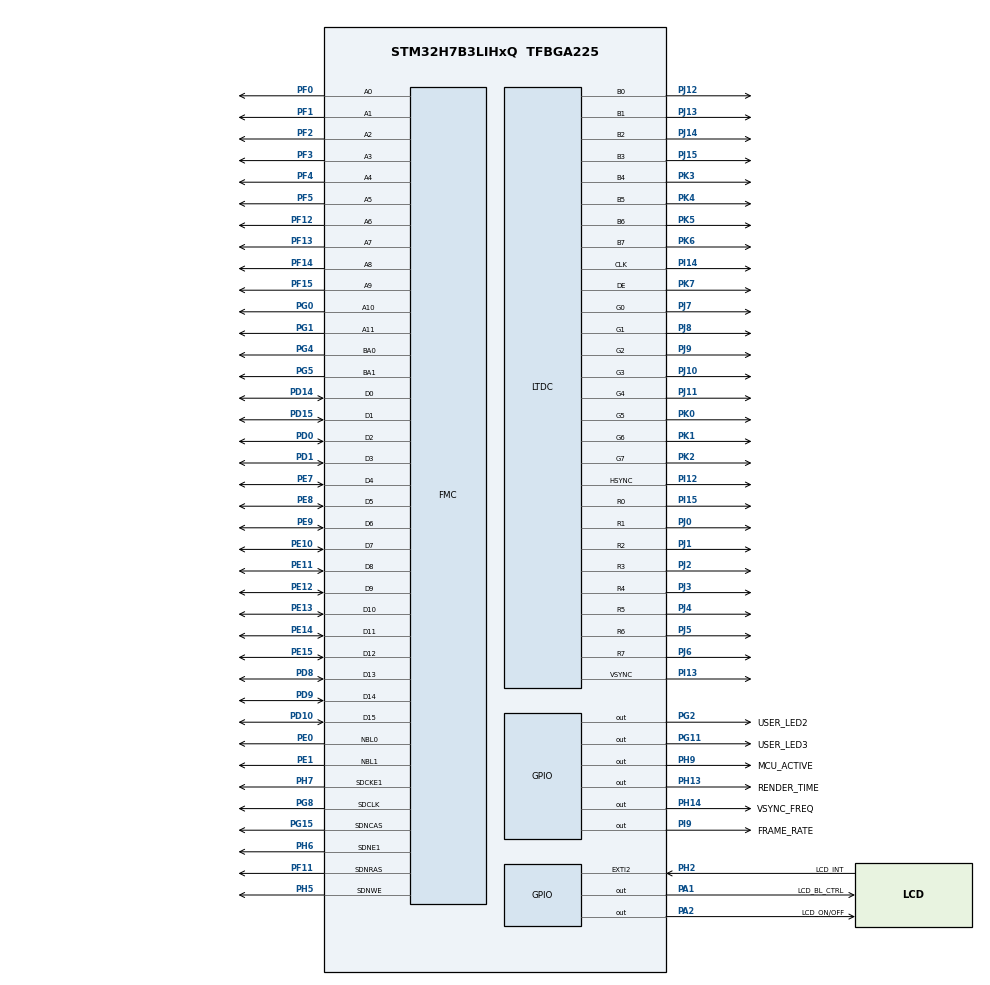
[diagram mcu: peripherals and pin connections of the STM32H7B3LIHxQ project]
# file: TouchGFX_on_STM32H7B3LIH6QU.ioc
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CORTEX_M7.default_mode_Activation=1
DMA2D.ColorMode=DMA2D_OUTPUT_RGB888
FMC.CASLatency1=FMC_SDRAM_CAS_LATENCY_2
FMC.ColumnBitsNumber1=FMC_SDRAM_COLUMN_BITS_NUM_9
FMC.ExitSelfRefreshDelay1=7
FMC.LoadToActiveDelay1=2
FMC.RCDDelay1=2
FMC.RPDelay1=2
FMC.ReadBurst1=FMC_SDRAM_RBURST_ENABLE
FMC.ReadPipeDelay1=FMC_SDRAM_RPIPE_DELAY_2
FMC.RowCycleDelay1=7
FMC.SDClockPeriod1=FMC_SDRAM_CLOCK_PERIOD_3
FMC.SelfRefreshTime1=4
FMC.WriteRecoveryTime1=3
FREERTOS.INCLUDE_vTaskCleanUpResources=0
FREERTOS.Tasks01=defaultTask,24,128,StartDefaultTask,Default,NULL,Dynamic,NULL,NULL;GUI_Task,24,8192,StartGUI_Task,Default,NULL,Dynamic,NULL,NULL
FREERTOS.configENABLE_FPU=0
FREERTOS.configTOTAL_HEAP_SIZE=100000
FREERTOS.configUSE_APPLICATION_TASK_TAG=1
FREERTOS.configUSE_IDLE_HOOK=1
FREERTOS.configUSE_NEWLIB_REENTRANT=1
LTDC.ActiveH=272
LTDC.ActiveW=480
LTDC.Alpha_L0=255
LTDC.Blue_L0=255
LTDC.FBStartAdress_L0=0xD0000000
LTDC.HBP=2
LTDC.HFP=32
LTDC.HSync=41
LTDC.ImageHeight_L0=272
LTDC.ImageWidth_L0=480
LTDC.Layers=0
LTDC.PixelFormat_L0=LTDC_PIXEL_FORMAT_RGB888
LTDC.VSync=10
LTDC.WindowX1_L0=480
LTDC.WindowY1_L0=272
Mcu.Family=STM32H7
Mcu.Name=STM32H7B3LIHxQ
Mcu.Package=TFBGA225
NVIC.DMA2D_IRQn=true\:5\:0\:false\:false\:true\:true\:true\:true\:true
NVIC.EXTI2_IRQn=true\:5\:0\:false\:false\:true\:false\:true\:true\:true
NVIC.LTDC_IRQn=true\:5\:0\:false\:false\:true\:true\:true\:true\:true
NVIC.PriorityGroup=NVIC_PRIORITYGROUP_4
NVIC.TIM6_DAC_IRQn=true\:0\:0\:true\:false\:true\:false\:false\:true\:true
NVIC.TimeBase=TIM6_DAC_IRQn
NVIC.TimeBaseIP=TIM6
OCTOSPI1.ChipSelectHighTime=2
OCTOSPI1.DeviceSize=26
PA1.GPIO_Label=LCD_BL_CTRL
PA1.PinState=GPIO_PIN_SET
PA1.Signal=GPIO_Output
PA13.Mode=Serial_Wire
PA13.Signal=DEBUG_JTMS-SWDIO
PA14.Mode=Serial_Wire
PA14.Signal=DEBUG_JTCK-SWCLK
PA2.GPIO_Label=LCD_ON/OFF
PA2.GPIO_PuPd=GPIO_PULLUP
PA2.PinState=GPIO_PIN_SET
PA2.Signal=GPIO_Output
PD0.Signal=FMC_D2_DA2
PD1.Signal=FMC_D3_DA3
PD10.Signal=FMC_D15_DA15
PD14.Signal=FMC_D0_DA0
PD15.Signal=FMC_D1_DA1
PD8.Signal=FMC_D13_DA13
PD9.Signal=FMC_D14_DA14
PE0.Signal=FMC_NBL0
PE1.Signal=FMC_NBL1
PE10.Signal=FMC_D7_DA7
PE11.Signal=FMC_D8_DA8
PE12.Signal=FMC_D9_DA9
PE13.Signal=FMC_D10_DA10
PE14.Signal=FMC_D11_DA11
PE15.Signal=FMC_D12_DA12
PE7.Signal=FMC_D4_DA4
PE8.Signal=FMC_D5_DA5
PE9.Signal=FMC_D6_DA6
PF0.Signal=FMC_A0
PF1.Signal=FMC_A1
PF11.Signal=FMC_SDNRAS
PF12.Signal=FMC_A6
PF13.Signal=FMC_A7
PF14.Signal=FMC_A8
PF15.Signal=FMC_A9
PF2.Signal=FMC_A2
PF3.Signal=FMC_A3
PF4.Signal=FMC_A4
PF5.Signal=FMC_A5
PG0.Signal=FMC_A10
PG1.Signal=FMC_A11
PG11.GPIO_Label=USER_LED3
PG11.PinState=GPIO_PIN_SET
PG11.Signal=GPIO_Output
PG15.Signal=FMC_SDNCAS
PG2.GPIO_Label=USER_LED2
PG2.PinState=GPIO_PIN_SET
PG2.Signal=GPIO_Output
PG4.Signal=FMC_A14_BA0
PG5.Signal=FMC_A15_BA1
PG8.Signal=FMC_SDCLK
PH0-OSC_IN.Mode=HSE-External-Oscillator
PH0-OSC_IN.Signal=RCC_OSC_IN
PH1-OSC_OUT.Mode=HSE-External-Oscillator
PH1-OSC_OUT.Signal=RCC_OSC_OUT
PH13.GPIO_Label=RENDER_TIME
PH13.GPIO_Speed=GPIO_SPEED_FREQ_VERY_HIGH
PH13.Signal=GPIO_Output
PH14.GPIO_Label=VSYNC_FREQ
PH14.GPIO_Speed=GPIO_SPEED_FREQ_VERY_HIGH
PH14.Signal=GPIO_Output
PH2.GPIO_Label=LCD_INT
PH2.GPIO_PuPd=GPIO_PULLUP
PH2.Signal=GPXTI2
PH5.Signal=FMC_SDNWE
PH6.Mode=SdramChipSelect2_1
PH6.Signal=FMC_SDNE1
PH7.Mode=SdramChipSelect2_1
PH7.Signal=FMC_SDCKE1
PH9.GPIO_Label=MCU_ACTIVE
PH9.GPIO_Speed=GPIO_SPEED_FREQ_VERY_HIGH
PH9.Signal=GPIO_Output
PI12.GPIO_Speed=GPIO_SPEED_FREQ_VERY_HIGH
PI12.Mode=RGB888
PI12.Signal=LTDC_HSYNC
PI13.GPIO_Speed=GPIO_SPEED_FREQ_VERY_HIGH
PI13.Mode=RGB888
PI13.Signal=LTDC_VSYNC
PI14.GPIO_Speed=GPIO_SPEED_FREQ_VERY_HIGH
PI14.Mode=RGB888
PI14.Signal=LTDC_CLK
PI15.GPIO_Speed=GPIO_SPEED_FREQ_VERY_HIGH
PI15.Mode=RGB888
PI15.Signal=LTDC_R0
PI9.GPIO_Label=FRAME_RATE
PI9.GPIO_Speed=GPIO_SPEED_FREQ_VERY_HIGH
PI9.Signal=GPIO_Output
PJ0.GPIO_Speed=GPIO_SPEED_FREQ_VERY_HIGH
PJ0.Mode=RGB888
PJ0.Signal=LTDC_R1
PJ1.GPIO_Speed=GPIO_SPEED_FREQ_VERY_HIGH
PJ1.Mode=RGB888
PJ1.Signal=LTDC_R2
PJ10.GPIO_Speed=GPIO_SPEED_FREQ_VERY_HIGH
PJ10.Mode=RGB888
PJ10.Signal=LTDC_G3
PJ11.GPIO_Speed=GPIO_SPEED_FREQ_VERY_HIGH
PJ11.Mode=RGB888
PJ11.Signal=LTDC_G4
PJ12.GPIO_Speed=GPIO_SPEED_FREQ_VERY_HIGH
PJ12.Mode=RGB888
PJ12.Signal=LTDC_B0
PJ13.GPIO_Speed=GPIO_SPEED_FREQ_VERY_HIGH
PJ13.Mode=RGB888
PJ13.Signal=LTDC_B1
PJ14.GPIO_Speed=GPIO_SPEED_FREQ_VERY_HIGH
PJ14.Mode=RGB888
PJ14.Signal=LTDC_B2
PJ15.GPIO_Speed=GPIO_SPEED_FREQ_VERY_HIGH
PJ15.Mode=RGB888
PJ15.Signal=LTDC_B3
PJ2.GPIO_Speed=GPIO_SPEED_FREQ_VERY_HIGH
PJ2.Mode=RGB888
PJ2.Signal=LTDC_R3
PJ3.GPIO_Speed=GPIO_SPEED_FREQ_VERY_HIGH
PJ3.Mode=RGB888
PJ3.Signal=LTDC_R4
PJ4.GPIO_Speed=GPIO_SPEED_FREQ_VERY_HIGH
PJ4.Mode=RGB888
PJ4.Signal=LTDC_R5
PJ5.GPIO_Speed=GPIO_SPEED_FREQ_VERY_HIGH
PJ5.Mode=RGB888
PJ5.Signal=LTDC_R6
PJ6.GPIO_Speed=GPIO_SPEED_FREQ_VERY_HIGH
PJ6.Mode=RGB888
PJ6.Signal=LTDC_R7
PJ7.GPIO_Speed=GPIO_SPEED_FREQ_VERY_HIGH
PJ7.Mode=RGB888
PJ7.Signal=LTDC_G0
PJ8.GPIO_Speed=GPIO_SPEED_FREQ_VERY_HIGH
PJ8.Mode=RGB888
PJ8.Signal=LTDC_G1
PJ9.GPIO_Speed=GPIO_SPEED_FREQ_VERY_HIGH
PJ9.Mode=RGB888
PJ9.Signal=LTDC_G2
PK0.GPIO_Speed=GPIO_SPEED_FREQ_VERY_HIGH
PK0.Mode=RGB888
PK0.Signal=LTDC_G5
PK1.GPIO_Speed=GPIO_SPEED_FREQ_VERY_HIGH
PK1.Mode=RGB888
PK1.Signal=LTDC_G6
PK2.GPIO_Speed=GPIO_SPEED_FREQ_VERY_HIGH
PK2.Mode=RGB888
PK2.Signal=LTDC_G7
PK3.GPIO_Speed=GPIO_SPEED_FREQ_VERY_HIGH
PK3.Mode=RGB888
PK3.Signal=LTDC_B4
PK4.GPIO_Speed=GPIO_SPEED_FREQ_VERY_HIGH
PK4.Mode=RGB888
PK4.Signal=LTDC_B5
PK5.GPIO_Speed=GPIO_SPEED_FREQ_VERY_HIGH
PK5.Mode=RGB888
PK5.Signal=LTDC_B6
PK6.GPIO_Speed=GPIO_SPEED_FREQ_VERY_HIGH
PK6.Mode=RGB888
PK6.Signal=LTDC_B7
PK7.GPIO_Speed=GPIO_SPEED_FREQ_VERY_HIGH
PK7.Mode=RGB888
PK7.Signal=LTDC_DE
ProjectManager.HeapSize=0x200
ProjectManager.StackSize=0x400
ProjectManager.TargetToolchain=STM32CubeIDE
RCC.ADCFreq_Value=133000000
RCC.APB1Freq_Value=70000000
RCC.APB2Freq_Value=70000000
RCC.APB3Freq_Value=70000000
RCC.APB4Freq_Value=70000000
RCC.CDPPRE=RCC_APB3_DIV2
RCC.CDPPRE1=RCC_APB1_DIV2
RCC.CDPPRE2=RCC_APB2_DIV2
RCC.CortexFreq_Value=280000000
RCC.DIVM1=12
RCC.DIVM2=24
RCC.DIVM3=24
RCC.DIVN1=280
RCC.DIVN2=266
RCC.DIVN3=201
RCC.DIVR3=21
RCC.HCLKFreq_Value=140000000
RCC.HPRE=RCC_HCLK_DIV2
RCC.PLL2FRACN=0
RCC.PLL3FRACN=5462
RCC.PLLFRACN=0
RCC.PLLSourceVirtual=RCC_PLLSOURCE_HSE
RCC.SRDPPRE=RCC_APB4_DIV2
RCC.SYSCLKFreq_VALUE=280000000
RCC.SYSCLKSource=RCC_SYSCLKSOURCE_PLLCLK
RCC.USBFreq_Value=280000000
SH.FMC_A0.0=FMC_A0,12b-sda1
SH.FMC_A1.0=FMC_A1,12b-sda1
SH.FMC_A10.0=FMC_A10,12b-sda1
SH.FMC_A11.0=FMC_A11,12b-sda1
SH.FMC_A14_BA0.0=FMC_BA0,FourSdramBanks1
SH.FMC_A15_BA1.0=FMC_BA1,FourSdramBanks1
SH.FMC_A2.0=FMC_A2,12b-sda1
SH.FMC_A3.0=FMC_A3,12b-sda1
SH.FMC_A4.0=FMC_A4,12b-sda1
SH.FMC_A5.0=FMC_A5,12b-sda1
SH.FMC_A6.0=FMC_A6,12b-sda1
SH.FMC_A7.0=FMC_A7,12b-sda1
SH.FMC_A8.0=FMC_A8,12b-sda1
SH.FMC_A9.0=FMC_A9,12b-sda1
SH.FMC_D0_DA0.0=FMC_D0,sd-16b-d1
SH.FMC_D10_DA10.0=FMC_D10,sd-16b-d1
SH.FMC_D11_DA11.0=FMC_D11,sd-16b-d1
SH.FMC_D12_DA12.0=FMC_D12,sd-16b-d1
SH.FMC_D13_DA13.0=FMC_D13,sd-16b-d1
SH.FMC_D14_DA14.0=FMC_D14,sd-16b-d1
SH.FMC_D15_DA15.0=FMC_D15,sd-16b-d1
SH.FMC_D1_DA1.0=FMC_D1,sd-16b-d1
SH.FMC_D2_DA2.0=FMC_D2,sd-16b-d1
SH.FMC_D3_DA3.0=FMC_D3,sd-16b-d1
SH.FMC_D4_DA4.0=FMC_D4,sd-16b-d1
SH.FMC_D5_DA5.0=FMC_D5,sd-16b-d1
SH.FMC_D6_DA6.0=FMC_D6,sd-16b-d1
SH.FMC_D7_DA7.0=FMC_D7,sd-16b-d1
SH.FMC_D8_DA8.0=FMC_D8,sd-16b-d1
SH.FMC_D9_DA9.0=FMC_D9,sd-16b-d1
SH.FMC_NBL0.0=FMC_NBL0,Sd2ByteEnable1
SH.FMC_NBL1.0=FMC_NBL1,Sd2ByteEnable1
SH.FMC_SDCLK.0=FMC_SDCLK,12b-sda1
SH.FMC_SDNCAS.0=FMC_SDNCAS,12b-sda1
SH.FMC_SDNRAS.0=FMC_SDNRAS,12b-sda1
SH.FMC_SDNWE.0=FMC_SDNWE,12b-sda1
STMicroelectronics.X-CUBE-TOUCHGFX.4.22.1.ApplicationCcGraphicsJjApplication=TouchGFXOoGenerator
STMicroelectronics.X-CUBE-TOUCHGFX.4.22.1.tgfx_address1=0xD0000000
STMicroelectronics.X-CUBE-TOUCHGFX.4.22.1.tgfx_buffering_strategy=Single
STMicroelectronics.X-CUBE-TOUCHGFX.4.22.1.tgfx_custom_height=272
STMicroelectronics.X-CUBE-TOUCHGFX.4.22.1.tgfx_display_interface=disp_ltdc
STMicroelectronics.X-CUBE-TOUCHGFX.4.22.1.tgfx_hardware_accelerator=dma_2d
STMicroelectronics.X-CUBE-TOUCHGFX.4.22.1.tgfx_location=By Address
STMicroelectronics.X-CUBE-TOUCHGFX.4.22.1.tgfx_pixel_format=RGB888\:24
STMicroelectronics.X-CUBE-TOUCHGFX.4.22.1.tgfx_vector_rendering=Enabled
STMicroelectronics.X-CUBE-TOUCHGFX.4.22.1.tgfx_vsync=vsync_ltdc
STMicroelectronics.X-CUBE-TOUCHGFX.4.22.1_IsPackSelfContextualization=true
VP_CRC_VS_CRC.Mode=CRC_Activate
VP_DMA2D_VS_DMA2D.Mode=DMA2D_Activate
VP_FREERTOS_VS_CMSIS_V2.Mode=CMSIS_V2
VP_OCTOSPI1_VS_octo.Mode=octo_mode
VP_STMicroelectronics.X-CUBE-TOUCHGFX_VS_GraphicsJjApplication_4.22.1.Mode=GraphicsJjApplication
VP_SYS_VS_tim6.Mode=TIM6
board=custom

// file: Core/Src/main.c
/* USER CODE BEGIN Header */
/**
  ******************************************************************************
  * @file           : main.c
  * @brief          : Main program body
  ******************************************************************************
  * @attention
  *
  * Copyright (c) 2023 STMicroelectronics.
  * All rights reserved.
  *
  * This software is licensed under terms that can be found in the LICENSE file
  * in the root directory of this software component.
  * If no LICENSE file comes with this software, it is provided AS-IS.
  *
  ******************************************************************************
  */
/* USER CODE END Header */
#include "main.h"
#include "cmsis_os.h"
#include "crc.h"
#include "dma2d.h"
#include "ltdc.h"
#include "octospi.h"
#include "gpio.h"
#include "fmc.h"
#include "app_touchgfx.h"

/* USER CODE BEGIN PV */

// ------------------------- Development board copied code start ----------------------------------
FMC_SDRAM_CommandTypeDef command;
// ------------------------- Development board copied code end ------------------------------------

/* USER CODE END PV */

void SystemClock_Config(void);
static void MPU_Initialize(void);
static void MPU_Config(void);
void MX_FREERTOS_Init(void);
/* USER CODE BEGIN PFP */

// ------------------------- Development board copied code start ----------------------------------

#define SDRAM_TIMEOUT                    ((uint32_t)0xFFFF)
#define REFRESH_COUNT                    ((uint32_t)0x0603)

#define SDRAM_MODEREG_BURST_LENGTH_1             ((uint16_t)0x0000)
#define SDRAM_MODEREG_BURST_LENGTH_2             ((uint16_t)0x0001)
#define SDRAM_MODEREG_BURST_LENGTH_4             ((uint16_t)0x0002)
#define SDRAM_MODEREG_BURST_LENGTH_8             ((uint16_t)0x0004)
#define SDRAM_MODEREG_BURST_TYPE_SEQUENTIAL      ((uint16_t)0x0000)
#define SDRAM_MODEREG_BURST_TYPE_INTERLEAVED     ((uint16_t)0x0008)
#define SDRAM_MODEREG_CAS_LATENCY_2              ((uint16_t)0x0020)
#define SDRAM_MODEREG_CAS_LATENCY_3              ((uint16_t)0x0030)
#define SDRAM_MODEREG_OPERATING_MODE_STANDARD    ((uint16_t)0x0000)
#define SDRAM_MODEREG_WRITEBURST_MODE_PROGRAMMED ((uint16_t)0x0000)
#define SDRAM_MODEREG_WRITEBURST_MODE_SINGLE     ((uint16_t)0x0200)

static void SDRAM_Initialization_Sequence(SDRAM_HandleTypeDef *hsdram, FMC_SDRAM_CommandTypeDef *Command);
// ------------------------- Development board copied code end ------------------------------------

/* USER CODE END PFP */

int main(void)
{

  /* MCU Configuration--------------------------------------------------------*/

  /* Reset of all peripherals, Initializes the Flash interface and the Systick. */
  HAL_Init();

  /* MPU Configuration--------------------------------------------------------*/
  MPU_Config();

  /* Configure the system clock */
  SystemClock_Config();

  /* Initialize all configured peripherals */
  MX_GPIO_Init();
  MX_DMA2D_Init();
  MX_FMC_Init();
  MX_OCTOSPI1_Init();
  MX_CRC_Init();
  MX_LTDC_Init();
  MX_TouchGFX_Init();
  /* Call PreOsInit function */
  MX_TouchGFX_PreOSInit();
  /* USER CODE BEGIN 2 */

  // ------------------------- Development board copied code start ----------------------------------

  // Note: When you use frame buffer by allocation (frame buffer will be located in internal memory) then in LTDC settings enter address 0.

  SDRAM_Initialization_Sequence(&hsdram1, &command);

  // *(__IO uint32_t*)(0xD0000000) = 0x11111122;  // this will cause mem error. What is the purpose of this line in example project?

  // ------------------------- Development board copied code end ------------------------------------

  /* USER CODE END 2 */

  /* Init scheduler */
  osKernelInitialize();  /* Call init function for freertos objects (in freertos.c) */
  MX_FREERTOS_Init();

  /* Start scheduler */
  osKernelStart();

  /* We should never get here as control is now taken by the scheduler */
  /* Infinite loop */
  while (1)
  {

  }
}

void SystemClock_Config(void)
{
  RCC_OscInitTypeDef RCC_OscInitStruct = {0};
  RCC_ClkInitTypeDef RCC_ClkInitStruct = {0};

  /*AXI clock gating */
  RCC->CKGAENR = 0xFFFFFFFF;

  /** Supply configuration update enable
  */
  HAL_PWREx_ConfigSupply(PWR_DIRECT_SMPS_SUPPLY);

  /** Configure the main internal regulator output voltage
  */
  __HAL_PWR_VOLTAGESCALING_CONFIG(PWR_REGULATOR_VOLTAGE_SCALE0);

  while(!__HAL_PWR_GET_FLAG(PWR_FLAG_VOSRDY)) {}

  /** Initializes the RCC Oscillators according to the specified parameters
  * in the RCC_OscInitTypeDef structure.
  */
  RCC_OscInitStruct.OscillatorType = RCC_OSCILLATORTYPE_HSE;
  RCC_OscInitStruct.HSEState = RCC_HSE_ON;
  RCC_OscInitStruct.PLL.PLLState = RCC_PLL_ON;
  RCC_OscInitStruct.PLL.PLLSource = RCC_PLLSOURCE_HSE;
  RCC_OscInitStruct.PLL.PLLM = 12;
  RCC_OscInitStruct.PLL.PLLN = 280;
  RCC_OscInitStruct.PLL.PLLP = 2;
  RCC_OscInitStruct.PLL.PLLQ = 2;
  RCC_OscInitStruct.PLL.PLLR = 2;
  RCC_OscInitStruct.PLL.PLLRGE = RCC_PLL1VCIRANGE_1;
  RCC_OscInitStruct.PLL.PLLVCOSEL = RCC_PLL1VCOWIDE;
  RCC_OscInitStruct.PLL.PLLFRACN = 0;
  if (HAL_RCC_OscConfig(&RCC_OscInitStruct) != HAL_OK)
  {
    Error_Handler();
  }

  /** Initializes the CPU, AHB and APB buses clocks
  */
  RCC_ClkInitStruct.ClockType = RCC_CLOCKTYPE_HCLK|RCC_CLOCKTYPE_SYSCLK
                              |RCC_CLOCKTYPE_PCLK1|RCC_CLOCKTYPE_PCLK2
                              |RCC_CLOCKTYPE_D3PCLK1|RCC_CLOCKTYPE_D1PCLK1;
  RCC_ClkInitStruct.SYSCLKSource = RCC_SYSCLKSOURCE_PLLCLK;
  RCC_ClkInitStruct.SYSCLKDivider = RCC_SYSCLK_DIV1;
  RCC_ClkInitStruct.AHBCLKDivider = RCC_HCLK_DIV2;
  RCC_ClkInitStruct.APB3CLKDivider = RCC_APB3_DIV2;
  RCC_ClkInitStruct.APB1CLKDivider = RCC_APB1_DIV2;
  RCC_ClkInitStruct.APB2CLKDivider = RCC_APB2_DIV2;
  RCC_ClkInitStruct.APB4CLKDivider = RCC_APB4_DIV2;

  if (HAL_RCC_ClockConfig(&RCC_ClkInitStruct, FLASH_LATENCY_3) != HAL_OK)
  {
    Error_Handler();
  }
}

/* USER CODE BEGIN 4 */

// ------------------------- Development board copied code start ----------------------------------
static void SDRAM_Initialization_Sequence(SDRAM_HandleTypeDef *hsdram, FMC_SDRAM_CommandTypeDef *Command)
{
  __IO uint32_t tmpmrd =0;
  /* Step 1:  Configure a clock configuration enable command */
  Command->CommandMode = FMC_SDRAM_CMD_CLK_ENABLE;
  Command->CommandTarget = FMC_SDRAM_CMD_TARGET_BANK2;
  Command->AutoRefreshNumber = 1;
  Command->ModeRegisterDefinition = 0;

  /* Send the command */
  HAL_SDRAM_SendCommand(hsdram, Command, SDRAM_TIMEOUT);

  /* Step 2: Insert 100 us minimum delay */
  /* Inserted delay is equal to 1 ms due to systick time base unit (ms) */
  HAL_Delay(1);

  /* Step 3: Configure a PALL (precharge all) command */
  Command->CommandMode = FMC_SDRAM_CMD_PALL;
  Command->CommandTarget = FMC_SDRAM_CMD_TARGET_BANK2;
  Command->AutoRefreshNumber = 1;
  Command->ModeRegisterDefinition = 0;

  /* Send the command */
  HAL_SDRAM_SendCommand(hsdram, Command, SDRAM_TIMEOUT);

  /* Step 4 : Configure a Auto-Refresh command */
  Command->CommandMode = FMC_SDRAM_CMD_AUTOREFRESH_MODE;
  Command->CommandTarget = FMC_SDRAM_CMD_TARGET_BANK2;
  Command->AutoRefreshNumber = 8;
  Command->ModeRegisterDefinition = 0;

  /* Send the command */
  HAL_SDRAM_SendCommand(hsdram, Command, SDRAM_TIMEOUT);

  /* Step 5: Program the external memory mode register */
  tmpmrd = (uint32_t)SDRAM_MODEREG_BURST_LENGTH_1          |
                     SDRAM_MODEREG_BURST_TYPE_SEQUENTIAL   |
                     SDRAM_MODEREG_CAS_LATENCY_2           |
                     SDRAM_MODEREG_OPERATING_MODE_STANDARD |
                     SDRAM_MODEREG_WRITEBURST_MODE_SINGLE;

  Command->CommandMode = FMC_SDRAM_CMD_LOAD_MODE;
  Command->CommandTarget = FMC_SDRAM_CMD_TARGET_BANK2;
  Command->AutoRefreshNumber = 1;
  Command->ModeRegisterDefinition = tmpmrd;

  /* Send the command */
  HAL_SDRAM_SendCommand(hsdram, Command, SDRAM_TIMEOUT);

  /* Step 6: Set the refresh rate counter */
  /* Set the device refresh rate */
  HAL_SDRAM_ProgramRefreshRate(hsdram, REFRESH_COUNT);

}
// ------------------------- Development board copied code end ------------------------------------

/* USER CODE END 4 */

/* MPU Configuration */

void MPU_Config(void)
{
  MPU_Region_InitTypeDef MPU_InitStruct = {0};

  /* Disables the MPU */
  HAL_MPU_Disable();

  /** Initializes and configures the Region and the memory to be protected
  */
  MPU_InitStruct.Enable = MPU_REGION_ENABLE;
  MPU_InitStruct.Number = MPU_REGION_NUMBER0;
  MPU_InitStruct.BaseAddress = 0x0;
  MPU_InitStruct.Size = MPU_REGION_SIZE_4GB;
  MPU_InitStruct.SubRegionDisable = 0x87;
  MPU_InitStruct.TypeExtField = MPU_TEX_LEVEL0;
  MPU_InitStruct.AccessPermission = MPU_REGION_NO_ACCESS;
  MPU_InitStruct.DisableExec = MPU_INSTRUCTION_ACCESS_DISABLE;
  MPU_InitStruct.IsShareable = MPU_ACCESS_SHAREABLE;
  MPU_InitStruct.IsCacheable = MPU_ACCESS_NOT_CACHEABLE;
  MPU_InitStruct.IsBufferable = MPU_ACCESS_NOT_BUFFERABLE;

  HAL_MPU_ConfigRegion(&MPU_InitStruct);
  /* Enables the MPU */
  HAL_MPU_Enable(MPU_PRIVILEGED_DEFAULT);

}

void HAL_TIM_PeriodElapsedCallback(TIM_HandleTypeDef *htim)
{
  if (htim->Instance == TIM6) {
    HAL_IncTick();
  }
}

void Error_Handler(void)
{
  __disable_irq();
  while (1)
  {
  }
}

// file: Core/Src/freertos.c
/* USER CODE BEGIN Header */
/**
  ******************************************************************************
  * File Name          : freertos.c
  * Description        : Code for freertos applications
  ******************************************************************************
  * @attention
  *
  * Copyright (c) 2023 STMicroelectronics.
  * All rights reserved.
  *
  * This software is licensed under terms that can be found in the LICENSE file
  * in the root directory of this software component.
  * If no LICENSE file comes with this software, it is provided AS-IS.
  *
  ******************************************************************************
  */
/* USER CODE END Header */

#include "FreeRTOS.h"
#include "task.h"
#include "main.h"
#include "cmsis_os.h"

/* USER CODE BEGIN Includes */

#include "app_touchgfx.h"

/* USER CODE END Includes */

/* Definitions for defaultTask */
osThreadId_t defaultTaskHandle;
const osThreadAttr_t defaultTask_attributes = {
  .name = "defaultTask",
  .stack_size = 128 * 4,
  .priority = (osPriority_t) osPriorityNormal,
};
/* Definitions for GUI_Task */
osThreadId_t GUI_TaskHandle;
const osThreadAttr_t GUI_Task_attributes = {
  .name = "GUI_Task",
  .stack_size = 8192 * 4,
  .priority = (osPriority_t) osPriorityNormal,
};

void StartDefaultTask(void *argument);
void StartGUI_Task(void *argument);

void MX_FREERTOS_Init(void); /* (MISRA C 2004 rule 8.1) */

/* Hook prototypes */
void vApplicationIdleHook(void);

/* USER CODE BEGIN 2 */
void vApplicationIdleHook( void )
{
   /* vApplicationIdleHook() will only be called if configUSE_IDLE_HOOK is set
   to 1 in FreeRTOSConfig.h. It will be called on each iteration of the idle
   task. It is essential that code added to this hook function never attempts
   to block in any way (for example, call xQueueReceive() with a block time
   specified, or call vTaskDelay()). If the application makes use of the
   vTaskDelete() API function (as this demo application does) then it is also
   important that vApplicationIdleHook() is permitted to return to its calling
   function, because it is the responsibility of the idle task to clean up
   memory allocated by the kernel to any task that has since been deleted. */
}
/* USER CODE END 2 */

void MX_FREERTOS_Init(void) {

  /* Create the thread(s) */
  /* creation of defaultTask */
  defaultTaskHandle = osThreadNew(StartDefaultTask, NULL, &defaultTask_attributes);

  /* creation of GUI_Task */
  GUI_TaskHandle = osThreadNew(StartGUI_Task, NULL, &GUI_Task_attributes);

}

void StartDefaultTask(void *argument)
{
  for(;;)
  {
    osDelay(1);
  }
}

void StartGUI_Task(void *argument)
{
  /* USER CODE BEGIN StartGUI_Task */

	MX_TouchGFX_Process();

  /* Infinite loop */
  for(;;)
  {
    osDelay(1);
  }
  /* USER CODE END StartGUI_Task */
}
